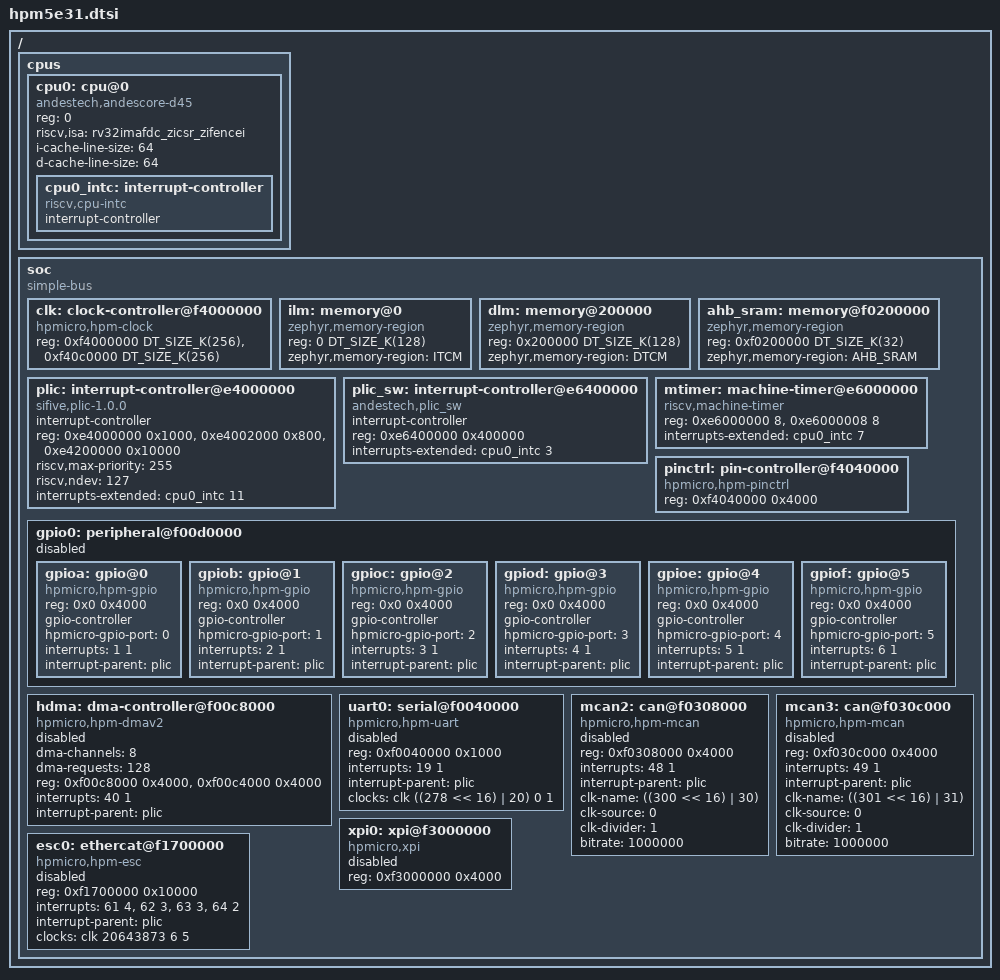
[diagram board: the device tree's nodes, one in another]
#include <mem.h>
#include <freq.h>

/ {
	#address-cells = <1>;
	#size-cells = <1>;

	cpus {
		#address-cells = <1>;
		#size-cells = <0>;

		cpu0: cpu@0 {
			compatible = "andestech,andescore-d45", "riscv";
			reg = <0>;
			status = "okay";
			riscv,isa = "rv32imafdc_zicsr_zifencei";
			i-cache-line-size = <64>;
			d-cache-line-size = <64>;

			cpu0_intc: interrupt-controller {
				compatible = "riscv,cpu-intc";
				#address-cells = <0>;
				#interrupt-cells = <1>;
				interrupt-controller;
			};
		};
	};

	soc {
		compatible = "simple-bus";
		#address-cells = <1>;
		#size-cells = <1>;
		ranges;

		clk: clock-controller@f4000000 {
			compatible = "hpmicro,hpm-clock";
			reg = <0xf4000000 DT_SIZE_K(256)>, <0xf40c0000 DT_SIZE_K(256)>;
			reg-names = "sysctl", "pllv2";
			#clock-cells = <3>;
			status = "okay";
		};

		ilm: memory@0 {
			compatible = "zephyr,memory-region";
			reg = <0 DT_SIZE_K(128)>;
			zephyr,memory-region = "ITCM";
		};

		dlm: memory@200000 {
			compatible = "zephyr,memory-region";
			reg = <0x200000 DT_SIZE_K(128)>;
			zephyr,memory-region = "DTCM";
		};

		ahb_sram: memory@f0200000 {
			compatible = "zephyr,memory-region";
			reg = <0xf0200000 DT_SIZE_K(32)>;
			zephyr,memory-region = "AHB_SRAM";
		};

		plic: interrupt-controller@e4000000 {
			compatible = "sifive,plic-1.0.0";
			#address-cells = <1>;
			#interrupt-cells = <2>;
			interrupt-controller;
			reg = <0xe4000000 0x1000>, <0xe4002000 0x800>, <0xe4200000 0x10000>;
			reg-names = "prio", "irq_en", "reg";
			riscv,max-priority = <255>;
			riscv,ndev = <127>;
			interrupts-extended = <&cpu0_intc 11>;
		};

		plic_sw: interrupt-controller@e6400000 {
			compatible = "andestech,plic_sw";
			#address-cells = <1>;
			#interrupt-cells = <2>;
			interrupt-controller;
			reg = <0xe6400000 0x400000>;
			interrupts-extended = <&cpu0_intc 3>;
		};

		mtimer: machine-timer@e6000000 {
			compatible = "riscv,machine-timer", "andestech,machine-timer";
			reg = <0xe6000000 8>, <0xe6000008 8>;
			reg-names = "mtime", "mtimecmp";
			interrupts-extended = <&cpu0_intc 7>;
		};

		pinctrl: pin-controller@f4040000 {
			compatible = "hpmicro,hpm-pinctrl";
			reg = <0xf4040000 0x4000>;
			status = "okay";
		};

		gpio0: peripheral@f00d0000 {
			#address-cells = <1>;
			#size-cells = <1>;
			ranges = <0x0 0xf00d0000 DT_SIZE_K(16)>;
			status = "disabled";
		};

		hdma: dma-controller@f00c8000 {
			compatible = "hpmicro,hpm-dmav2";
			#dma-cells = <2>;
			dma-channels = <8>;
			dma-requests = <128>;
			reg = <0xf00c8000 0x4000>, <0xf00c4000 0x4000>;
			interrupts = <40 1>;
			interrupt-parent = <&plic>;
			status = "disabled";
		};

		uart0: serial@f0040000 {
			compatible = "hpmicro,hpm-uart";
			reg = <0xf0040000 0x1000>;
			interrupts = <19 1>;
			interrupt-names = "uart";
			interrupt-parent = <&plic>;
			clocks = <&clk ((278 << 16) | 20) 0 1>;
			status = "disabled";
		};

		mcan2: can@f0308000 {
			compatible = "hpmicro,hpm-mcan";
			reg = <0xf0308000 0x4000>;
			interrupts = <48 1>;
			interrupt-parent = <&plic>;
			clk-name = <((300 << 16) | 30)>;
			clk-source = <0>;
			clk-divider = <1>;
			bitrate = <1000000>;
			status = "disabled";
		};

		mcan3: can@f030c000 {
			compatible = "hpmicro,hpm-mcan";
			reg = <0xf030c000 0x4000>;
			interrupts = <49 1>;
			interrupt-parent = <&plic>;
			clk-name = <((301 << 16) | 31)>;
			clk-source = <0>;
			clk-divider = <1>;
			bitrate = <1000000>;
			status = "disabled";
		};

		xpi0: xpi@f3000000 {
			compatible = "hpmicro,xpi";
			reg = <0xf3000000 0x4000>;
			#address-cells = <1>;
			#size-cells = <1>;
			status = "disabled";
		};

		esc0: ethercat@f1700000 {
			compatible = "hpmicro,hpm-esc";
			reg = <0xf1700000 0x10000>;
			interrupts = <61 4>, <62 3>, <63 3>, <64 2>;
			interrupt-names = "pdi", "sync0", "sync1", "reset";
			interrupt-parent = <&plic>;
			clocks = <&clk 20643873 6 5>;
			status = "disabled";
		};
	};
};

&gpio0 {
	gpioa: gpio@0 {
		compatible = "hpmicro,hpm-gpio";
		reg = <0x0 0x4000>;
		gpio-controller;
		#gpio-cells = <2>;
		hpmicro-gpio-port = <0>;
		interrupts = <1 1>;
		interrupt-parent = <&plic>;
	};

	gpiob: gpio@1 {
		compatible = "hpmicro,hpm-gpio";
		reg = <0x0 0x4000>;
		gpio-controller;
		#gpio-cells = <2>;
		hpmicro-gpio-port = <1>;
		interrupts = <2 1>;
		interrupt-parent = <&plic>;
	};

	gpioc: gpio@2 {
		compatible = "hpmicro,hpm-gpio";
		reg = <0x0 0x4000>;
		gpio-controller;
		#gpio-cells = <2>;
		hpmicro-gpio-port = <2>;
		interrupts = <3 1>;
		interrupt-parent = <&plic>;
	};

	gpiod: gpio@3 {
		compatible = "hpmicro,hpm-gpio";
		reg = <0x0 0x4000>;
		gpio-controller;
		#gpio-cells = <2>;
		hpmicro-gpio-port = <3>;
		interrupts = <4 1>;
		interrupt-parent = <&plic>;
	};

	gpioe: gpio@4 {
		compatible = "hpmicro,hpm-gpio";
		reg = <0x0 0x4000>;
		gpio-controller;
		#gpio-cells = <2>;
		hpmicro-gpio-port = <4>;
		interrupts = <5 1>;
		interrupt-parent = <&plic>;
	};

	gpiof: gpio@5 {
		compatible = "hpmicro,hpm-gpio";
		reg = <0x0 0x4000>;
		gpio-controller;
		#gpio-cells = <2>;
		hpmicro-gpio-port = <5>;
		interrupts = <6 1>;
		interrupt-parent = <&plic>;
	};
};
